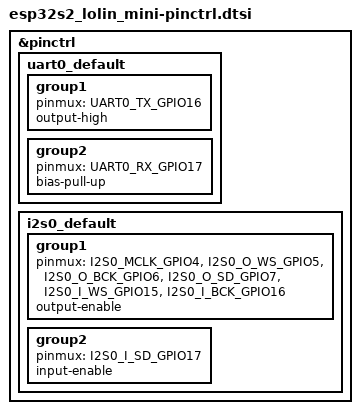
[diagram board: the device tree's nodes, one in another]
/*
 * Copyright (c) 2023 Google, LLC
 * Copyright (c) 2025 Espressif Systems (Shanghai) Co., Ltd.
 *
 * SPDX-License-Identifier: Apache-2.0
 */

#include <zephyr/dt-bindings/pinctrl/esp-pinctrl-common.h>
#include <dt-bindings/pinctrl/esp32s2-pinctrl.h>
#include <zephyr/dt-bindings/pinctrl/esp32s2-gpio-sigmap.h>

&pinctrl {

	uart0_default: uart0_default {
		group1 {
			pinmux = <UART0_TX_GPIO16>;
			output-high;
		};
		group2 {
			pinmux = <UART0_RX_GPIO17>;
			bias-pull-up;
		};
	};

	i2s0_default: i2s0_default {
		group1 {
			pinmux = <I2S0_MCLK_GPIO4>,
				 <I2S0_O_WS_GPIO5>,
				 <I2S0_O_BCK_GPIO6>,
				 <I2S0_O_SD_GPIO7>,
				 <I2S0_I_WS_GPIO15>,
				 <I2S0_I_BCK_GPIO16>;
			output-enable;
		};
		group2 {
			pinmux = <I2S0_I_SD_GPIO17>;
			input-enable;
		};
	};
};
